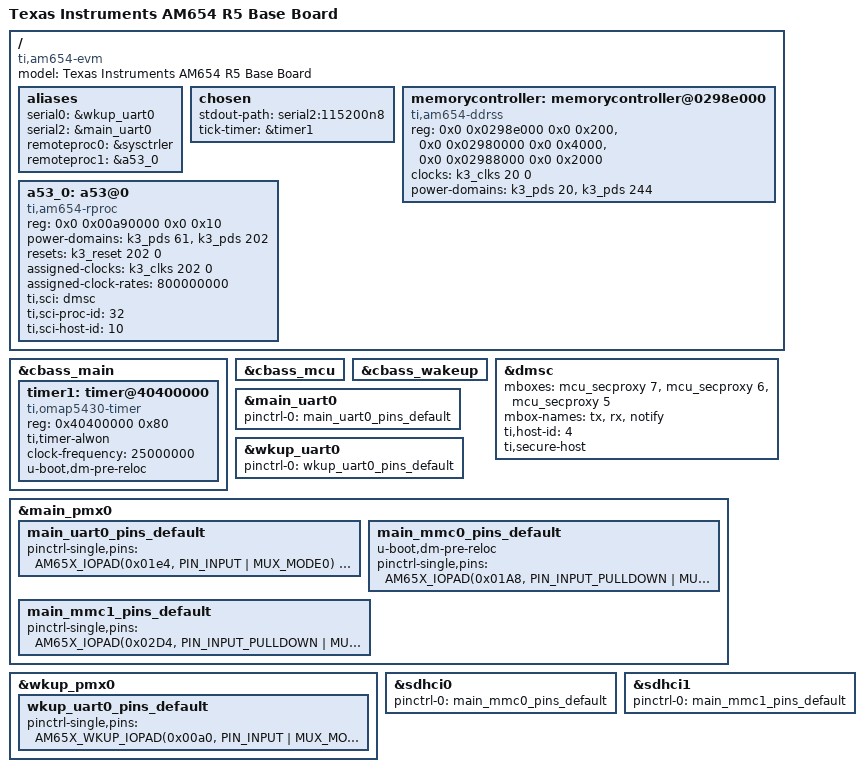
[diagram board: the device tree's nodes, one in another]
// SPDX-License-Identifier: GPL-2.0
/*
 * Copyright (C) 2016-2018 Texas Instruments Incorporated - http://www.ti.com/
 */

/dts-v1/;

#include "k3-am654.dtsi"
#include "k3-am65-mcu.dtsi"
#include "k3-am65-wakeup.dtsi"
#include "k3-am654-base-board-u-boot.dtsi"

/ {
	compatible =  "ti,am654-evm", "ti,am654";
	model = "Texas Instruments AM654 R5 Base Board";

	aliases {
		serial0 = &wkup_uart0;
		serial2 = &main_uart0;
	};

	chosen {
		stdout-path = "serial2:115200n8";
		tick-timer = &timer1;
	};

	aliases {
		remoteproc0 = &sysctrler;
		remoteproc1 = &a53_0;
	};

	memorycontroller: memorycontroller@0298e000 {
		compatible = "ti,am654-ddrss";
		reg = <0x0 0x0298e000 0x0 0x200>,
		      <0x0 0x02980000 0x0 0x4000>,
		      <0x0 0x02988000 0x0 0x2000>;
		reg-names = "ss", "ctl", "phy";
		clocks = <&k3_clks 20 0>;
		power-domains = <&k3_pds 20>,
				<&k3_pds 244>;
		u-boot,dm-spl;
	};

	a53_0: a53@0 {
		compatible = "ti,am654-rproc";
		reg = <0x0 0x00a90000 0x0 0x10>;
		power-domains = <&k3_pds 61>,
				<&k3_pds 202>;
		resets = <&k3_reset 202 0>;
		assigned-clocks = <&k3_clks 202 0>;
		assigned-clock-rates = <800000000>;
		ti,sci = <&dmsc>;
		ti,sci-proc-id = <32>;
		ti,sci-host-id = <10>;
		u-boot,dm-spl;
	};
};

&cbass_main {
	timer1: timer@40400000 {
		compatible = "ti,omap5430-timer";
		reg = <0x40400000 0x80>;
		ti,timer-alwon;
		clock-frequency = <25000000>;
		u-boot,dm-pre-reloc;
	};
};

&cbass_mcu {
	u-boot,dm-spl;
};

&cbass_wakeup {
	u-boot,dm-spl;
};

&dmsc {
	u-boot,dm-spl;
	mboxes= <&mcu_secproxy 7>, <&mcu_secproxy 6>, <&mcu_secproxy 5>;
	mbox-names = "tx", "rx", "notify";
	ti,host-id = <4>;
	ti,secure-host;
};

&main_uart0 {
	u-boot,dm-spl;
	pinctrl-names = "default";
	pinctrl-0 = <&main_uart0_pins_default>;
	status = "okay";
};

&wkup_uart0 {
	u-boot,dm-spl;
	pinctrl-names = "default";
	pinctrl-0 = <&wkup_uart0_pins_default>;
	status = "okay";
};

&main_pmx0 {
	u-boot,dm-spl;
	main_uart0_pins_default: main_uart0_pins_default {
		pinctrl-single,pins = <
			AM65X_IOPAD(0x01e4, PIN_INPUT | MUX_MODE0)	/* (AF11) UART0_RXD */
			AM65X_IOPAD(0x01e8, PIN_OUTPUT | MUX_MODE0)	/* (AE11) UART0_TXD */
			AM65X_IOPAD(0x01ec, PIN_INPUT | MUX_MODE0)	/* (AG11) UART0_CTSn */
			AM65X_IOPAD(0x01f0, PIN_OUTPUT | MUX_MODE0)	/* (AD11) UART0_RTSn */
		>;
		u-boot,dm-spl;
	};

	main_mmc0_pins_default: main_mmc0_pins_default {
		u-boot,dm-pre-reloc;
		pinctrl-single,pins = <
			AM65X_IOPAD(0x01A8, PIN_INPUT_PULLDOWN | MUX_MODE0) /* (B25) MMC0_CLK */
			AM65X_IOPAD(0x01AC, PIN_INPUT_PULLUP | MUX_MODE0) /* (B27) MMC0_CMD */
			AM65X_IOPAD(0x01A4, PIN_INPUT_PULLUP | MUX_MODE0) /* (A26) MMC0_DAT0 */
			AM65X_IOPAD(0x01A0, PIN_INPUT_PULLUP | MUX_MODE0) /* (E25) MMC0_DAT1 */
			AM65X_IOPAD(0x019C, PIN_INPUT_PULLUP | MUX_MODE0) /* (C26) MMC0_DAT2 */
			AM65X_IOPAD(0x0198, PIN_INPUT_PULLUP | MUX_MODE0) /* (A25) MMC0_DAT3 */
			AM65X_IOPAD(0x0194, PIN_INPUT_PULLUP | MUX_MODE0) /* (E24) MMC0_DAT4 */
			AM65X_IOPAD(0x0190, PIN_INPUT_PULLUP | MUX_MODE0) /* (A24) MMC0_DAT5 */
			AM65X_IOPAD(0x018C, PIN_INPUT_PULLUP | MUX_MODE0) /* (B26) MMC0_DAT6 */
			AM65X_IOPAD(0x0188, PIN_INPUT_PULLUP | MUX_MODE0) /* (D25) MMC0_DAT7 */
			AM65X_IOPAD(0x01B4, PIN_INPUT_PULLUP | MUX_MODE0) /* (A23) MMC0_SDCD */
			AM65X_IOPAD(0x01B8, PIN_INPUT | MUX_MODE0) /* (B23) MMC0_SDWP */
			AM65X_IOPAD(0x01B0, PIN_INPUT | MUX_MODE0) /* (C25) MMC0_DS */
		>;
		u-boot,dm-spl;
	};

	main_mmc1_pins_default: main_mmc1_pins_default {
		pinctrl-single,pins = <
			AM65X_IOPAD(0x02D4, PIN_INPUT_PULLDOWN | MUX_MODE0) /* (C27) MMC1_CLK */
			AM65X_IOPAD(0x02D8, PIN_INPUT_PULLUP | MUX_MODE0) /* (C28) MMC1_CMD */
			AM65X_IOPAD(0x02D0, PIN_INPUT_PULLUP | MUX_MODE0) /* (D28) MMC1_DAT0 */
			AM65X_IOPAD(0x02CC, PIN_INPUT_PULLUP | MUX_MODE0) /* (E27) MMC1_DAT1 */
			AM65X_IOPAD(0x02C8, PIN_INPUT_PULLUP | MUX_MODE0) /* (D26) MMC1_DAT2 */
			AM65X_IOPAD(0x02C4, PIN_INPUT_PULLUP | MUX_MODE0) /* (D27) MMC1_DAT3 */
			AM65X_IOPAD(0x02DC, PIN_INPUT_PULLUP | MUX_MODE0) /* (B24) MMC1_SDCD */
			AM65X_IOPAD(0x02E0, PIN_INPUT | MUX_MODE0) /* (C24) MMC1_SDWP */
		>;
		u-boot,dm-spl;
	};
};

&wkup_pmx0 {
	u-boot,dm-spl;
	wkup_uart0_pins_default: wkup_uart0_pins_default {
		pinctrl-single,pins = <
			AM65X_WKUP_IOPAD(0x00a0, PIN_INPUT | MUX_MODE0) /* (AB1) WKUP_UART0_RXD */
			AM65X_WKUP_IOPAD(0x00a4, PIN_OUTPUT | MUX_MODE0) /* (AB5) WKUP_UART0_TXD */
			AM65X_WKUP_IOPAD(0x00c8, PIN_INPUT | MUX_MODE1) /* (AC2) WKUP_GPIO0_6.WKUP_UART0_CTSn */
			AM65X_WKUP_IOPAD(0x00cc, PIN_OUTPUT | MUX_MODE1) /* (AC1) WKUP_GPIO0_7.WKUP_UART0_RTSn */
		>;
		u-boot,dm-spl;
	};

};

&sdhci0 {
	u-boot,dm-spl;
	pinctrl-names = "default";
	pinctrl-0 = <&main_mmc0_pins_default>;
};

&sdhci1 {
	u-boot,dm-spl;
	pinctrl-names = "default";
	pinctrl-0 = <&main_mmc1_pins_default>;
};
